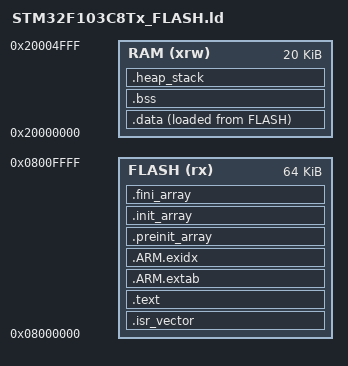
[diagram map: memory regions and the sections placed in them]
ENTRY(Reset_Handler)
MEMORY
{
  FLASH (rx) : ORIGIN = 0x08000000, LENGTH = 64K
  RAM (xrw)  : ORIGIN = 0x20000000, LENGTH = 20K
}
_estack = ORIGIN(RAM) + LENGTH(RAM);
SECTIONS
{
  .isr_vector : { . = ALIGN(4); KEEP(*(.isr_vector)) } > FLASH
  .text :
  {
    . = ALIGN(4);
    *(.text*) *(.rodata*)
    KEEP(*(.init)) KEEP(*(.fini))
    . = ALIGN(4);
    _etext = .;
  } > FLASH
  .ARM.extab : { *(.ARM.extab* .gnu.linkonce.armextab.*) } > FLASH
  .ARM.exidx :
  {
    __exidx_start = .;
    *(.ARM.exidx*)
    __exidx_end = .;
  } > FLASH
  .preinit_array (READONLY) :
  {
    PROVIDE_HIDDEN(__preinit_array_start = .);
    KEEP(*(.preinit_array*))
    PROVIDE_HIDDEN(__preinit_array_end = .);
  } > FLASH
  .init_array (READONLY) :
  {
    PROVIDE_HIDDEN(__init_array_start = .);
    KEEP(*(SORT(.init_array.*))) KEEP(*(.init_array*))
    PROVIDE_HIDDEN(__init_array_end = .);
  } > FLASH
  .fini_array (READONLY) :
  {
    PROVIDE_HIDDEN(__fini_array_start = .);
    KEEP(*(SORT(.fini_array.*))) KEEP(*(.fini_array*))
    PROVIDE_HIDDEN(__fini_array_end = .);
  } > FLASH
  _sidata = LOADADDR(.data);
  .data :
  {
    . = ALIGN(4); _sdata = .;
    *(.data*)
    . = ALIGN(4); _edata = .;
  } > RAM AT > FLASH
  .bss (NOLOAD) :
  {
    . = ALIGN(4); _sbss = .;
    *(.bss*) *(COMMON)
    . = ALIGN(4); _ebss = .;
  } > RAM
  .heap_stack (NOLOAD) :
  {
    . = ALIGN(8);
    _heap_start = .;
    . += 0x400;
    _heap_end = .;
    . += 0x400;
    . = ALIGN(8);
  } > RAM
  ASSERT(. <= _estack, "RAM overflow: heap and main stack do not fit")
}
